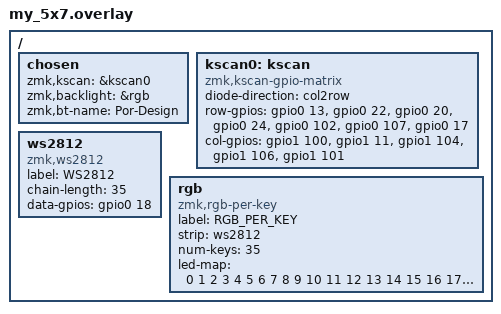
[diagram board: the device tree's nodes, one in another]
/ {
    chosen {
        zmk,kscan = &kscan0;
        zmk,backlight = &rgb;
        zmk,bt-name = "Por-Design";   /* ตั้งชื่อ Bluetooth */
    };

    kscan0: kscan {
        compatible = "zmk,kscan-gpio-matrix";
        diode-direction = "col2row";

        /* Rows 5 แถว */

 /* กำหนดขาแถว */
        row-gpios = <&gpio0 13 (GPIO_ACTIVE_HIGH | GPIO_PULL_DOWN)>,
                    <&gpio0 22 (GPIO_ACTIVE_HIGH | GPIO_PULL_DOWN)>,
                    <&gpio0 20 (GPIO_ACTIVE_HIGH | GPIO_PULL_DOWN)>,
                    <&gpio0 24 (GPIO_ACTIVE_HIGH | GPIO_PULL_DOWN)>,
                    <&gpio0 102 (GPIO_ACTIVE_HIGH | GPIO_PULL_DOWN)>,
                    <&gpio0 107 (GPIO_ACTIVE_HIGH | GPIO_PULL_DOWN)>,
                    <&gpio0 17 (GPIO_ACTIVE_HIGH | GPIO_PULL_DOWN)>;

        /* กำหนดขาคอลัมน์ */
        col-gpios = <&gpio1 100 GPIO_ACTIVE_HIGH>,
                    <&gpio1 11 GPIO_ACTIVE_HIGH>,
                    <&gpio1 104 GPIO_ACTIVE_HIGH>,
                    <&gpio1 106 GPIO_ACTIVE_HIGH>,
                    <&gpio1 101 GPIO_ACTIVE_HIGH>;

    };

    /* WS2812 RGB */
    ws2812: ws2812 {
        compatible = "zmk,ws2812";
        label = "WS2812";
        chain-length = <35>;
        data-gpios = <&gpio0 18 GPIO_ACTIVE_HIGH>; /* แนะนำใช้ P0.18 */
    };

    rgb: rgb {
        compatible = "zmk,rgb-per-key";
        label = "RGB_PER_KEY";
        strip = <&ws2812>;
        num-keys = <35>;

        led-map = <
             0  1  2  3  4  5  6
             7  8  9 10 11 12 13
            14 15 16 17 18 19 20
            21 22 23 24 25 26 27
            28 29 30 31 32 33 34
        >;
    };
};
